# ESP32C3 register map
File version: 1.0
CPU: RISC-V RV32IMC single-core 1, little endian, no MPU, FPU, 3 interrupt priority bits
Registers are 32-bit, read-write, reset 0x0 unless marked. A register's access mark holds for its fields unless they carry their own. Offsets are from the block's base; [hi:lo] are bit positions; {n}, {i} and the like mark numbered series.

## RTCCNTL
Base 0x60008000
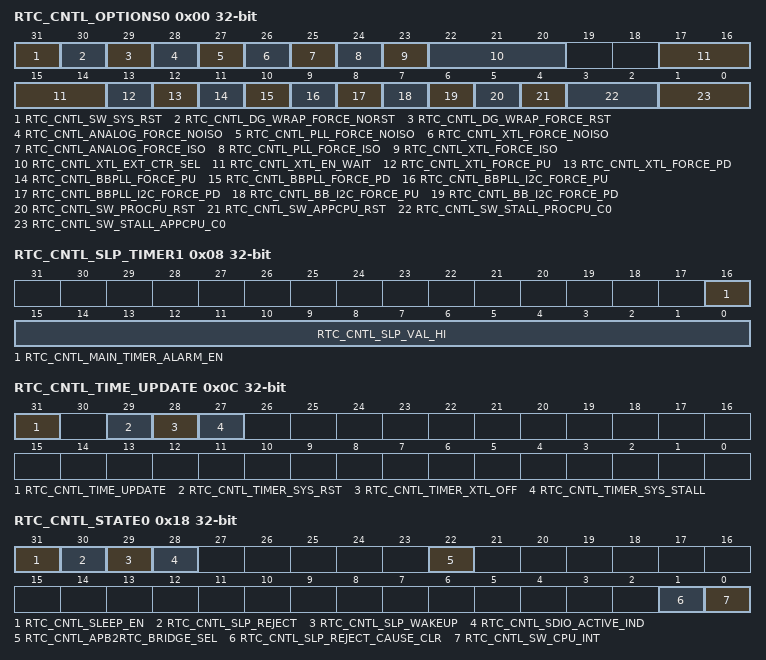
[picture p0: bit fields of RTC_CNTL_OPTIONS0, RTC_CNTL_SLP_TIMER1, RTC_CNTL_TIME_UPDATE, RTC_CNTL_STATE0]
0x00 RTC_CNTL_OPTIONS0 access per field
  [31] RTC_CNTL_SW_SYS_RST wo, [30] RTC_CNTL_DG_WRAP_FORCE_NORST rw, [29] RTC_CNTL_DG_WRAP_FORCE_RST rw, [28] RTC_CNTL_ANALOG_FORCE_NOISO rw, [27] RTC_CNTL_PLL_FORCE_NOISO rw, [26] RTC_CNTL_XTL_FORCE_NOISO rw, [25] RTC_CNTL_ANALOG_FORCE_ISO rw, [24] RTC_CNTL_PLL_FORCE_ISO rw, [23] RTC_CNTL_XTL_FORCE_ISO rw, [22:20] RTC_CNTL_XTL_EXT_CTR_SEL rw, [17:14] RTC_CNTL_XTL_EN_WAIT rw, [13] RTC_CNTL_XTL_FORCE_PU rw, [12] RTC_CNTL_XTL_FORCE_PD rw, [11] RTC_CNTL_BBPLL_FORCE_PU rw, [10] RTC_CNTL_BBPLL_FORCE_PD rw, [9] RTC_CNTL_BBPLL_I2C_FORCE_PU rw, [8] RTC_CNTL_BBPLL_I2C_FORCE_PD rw, [7] RTC_CNTL_BB_I2C_FORCE_PU rw, [6] RTC_CNTL_BB_I2C_FORCE_PD rw, [5] RTC_CNTL_SW_PROCPU_RST wo, [4] RTC_CNTL_SW_APPCPU_RST wo, [3:2] RTC_CNTL_SW_STALL_PROCPU_C0 rw, [1:0] RTC_CNTL_SW_STALL_APPCPU_C0 rw
0x04 RTC_CNTL_SLP_TIMER0
  [31:0] RTC_CNTL_SLP_VAL_LO
0x08 RTC_CNTL_SLP_TIMER1 access per field
  [16] RTC_CNTL_MAIN_TIMER_ALARM_EN wo, [15:0] RTC_CNTL_SLP_VAL_HI rw
0x0C RTC_CNTL_TIME_UPDATE access per field
  [31] RTC_CNTL_TIME_UPDATE wo, [29] RTC_CNTL_TIMER_SYS_RST rw, [28] RTC_CNTL_TIMER_XTL_OFF rw, [27] RTC_CNTL_TIMER_SYS_STALL rw
0x10 RTC_CNTL_TIME_LOW0 ro
  [31:0] RTC_CNTL_TIMER_VALUE0_LOW
0x14 RTC_CNTL_TIME_HIGH0 ro
  [15:0] RTC_CNTL_TIMER_VALUE0_HIGH
0x18 RTC_CNTL_STATE0 access per field
  [31] RTC_CNTL_SLEEP_EN rw, [30] RTC_CNTL_SLP_REJECT rw, [29] RTC_CNTL_SLP_WAKEUP rw, [28] RTC_CNTL_SDIO_ACTIVE_IND ro, [22] RTC_CNTL_APB2RTC_BRIDGE_SEL rw, [1] RTC_CNTL_SLP_REJECT_CAUSE_CLR wo, [0] RTC_CNTL_SW_CPU_INT wo
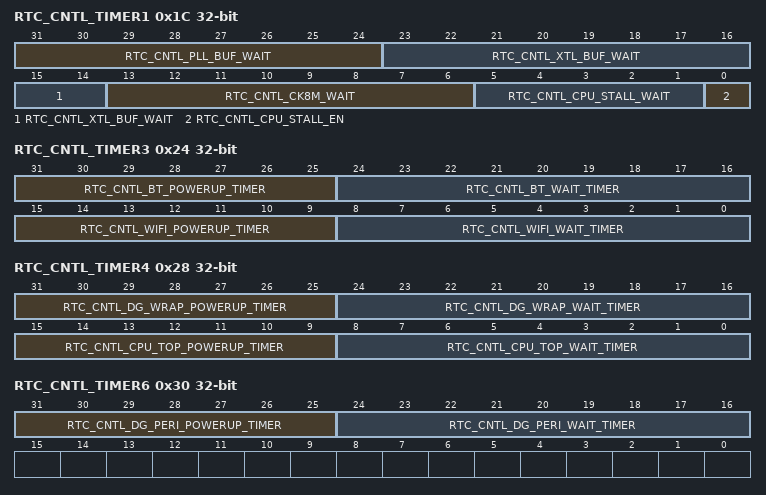
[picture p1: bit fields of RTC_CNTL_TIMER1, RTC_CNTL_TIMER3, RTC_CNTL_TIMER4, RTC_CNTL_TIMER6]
0x1C RTC_CNTL_TIMER1
  [31:24] RTC_CNTL_PLL_BUF_WAIT, [23:14] RTC_CNTL_XTL_BUF_WAIT, [13:6] RTC_CNTL_CK8M_WAIT, [5:1] RTC_CNTL_CPU_STALL_WAIT, [0] RTC_CNTL_CPU_STALL_EN
0x20 RTC_CNTL_TIMER2
  [31:24] RTC_CNTL_MIN_TIME_CK8M_OFF
0x24 RTC_CNTL_TIMER3
  [31:25] RTC_CNTL_BT_POWERUP_TIMER, [24:16] RTC_CNTL_BT_WAIT_TIMER, [15:9] RTC_CNTL_WIFI_POWERUP_TIMER, [8:0] RTC_CNTL_WIFI_WAIT_TIMER
0x28 RTC_CNTL_TIMER4
  [31:25] RTC_CNTL_DG_WRAP_POWERUP_TIMER, [24:16] RTC_CNTL_DG_WRAP_WAIT_TIMER, [15:9] RTC_CNTL_CPU_TOP_POWERUP_TIMER, [8:0] RTC_CNTL_CPU_TOP_WAIT_TIMER
0x2C RTC_CNTL_TIMER5
  [15:8] RTC_CNTL_MIN_SLP_VAL
0x30 RTC_CNTL_TIMER6
  [31:25] RTC_CNTL_DG_PERI_POWERUP_TIMER, [24:16] RTC_CNTL_DG_PERI_WAIT_TIMER
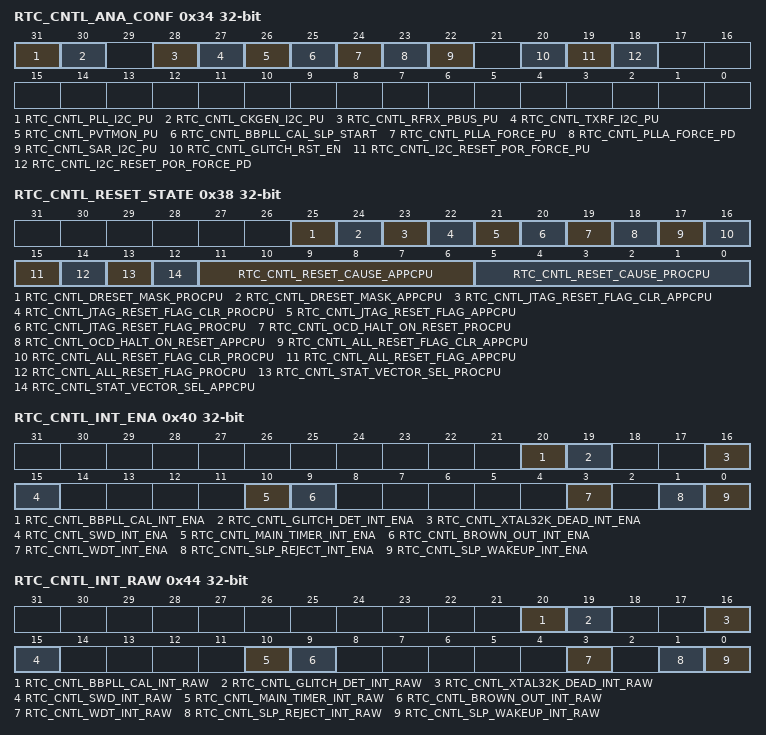
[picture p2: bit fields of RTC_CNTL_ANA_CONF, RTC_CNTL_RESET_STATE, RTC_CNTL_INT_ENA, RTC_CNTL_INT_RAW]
0x34 RTC_CNTL_ANA_CONF
  [31] RTC_CNTL_PLL_I2C_PU, [30] RTC_CNTL_CKGEN_I2C_PU, [28] RTC_CNTL_RFRX_PBUS_PU, [27] RTC_CNTL_TXRF_I2C_PU, [26] RTC_CNTL_PVTMON_PU, [25] RTC_CNTL_BBPLL_CAL_SLP_START, [24] RTC_CNTL_PLLA_FORCE_PU, [23] RTC_CNTL_PLLA_FORCE_PD, [22] RTC_CNTL_SAR_I2C_PU, [20] RTC_CNTL_GLITCH_RST_EN, [19] RTC_CNTL_I2C_RESET_POR_FORCE_PU, [18] RTC_CNTL_I2C_RESET_POR_FORCE_PD
0x38 RTC_CNTL_RESET_STATE access per field
  [25] RTC_CNTL_DRESET_MASK_PROCPU rw, [24] RTC_CNTL_DRESET_MASK_APPCPU rw, [23] RTC_CNTL_JTAG_RESET_FLAG_CLR_APPCPU wo, [22] RTC_CNTL_JTAG_RESET_FLAG_CLR_PROCPU wo, [21] RTC_CNTL_JTAG_RESET_FLAG_APPCPU ro, [20] RTC_CNTL_JTAG_RESET_FLAG_PROCPU ro, [19] RTC_CNTL_OCD_HALT_ON_RESET_PROCPU rw, [18] RTC_CNTL_OCD_HALT_ON_RESET_APPCPU rw, [17] RTC_CNTL_ALL_RESET_FLAG_CLR_APPCPU wo, [16] RTC_CNTL_ALL_RESET_FLAG_CLR_PROCPU wo, [15] RTC_CNTL_ALL_RESET_FLAG_APPCPU ro, [14] RTC_CNTL_ALL_RESET_FLAG_PROCPU ro, [13] RTC_CNTL_STAT_VECTOR_SEL_PROCPU rw, [12] RTC_CNTL_STAT_VECTOR_SEL_APPCPU rw, [11:6] RTC_CNTL_RESET_CAUSE_APPCPU ro, [5:0] RTC_CNTL_RESET_CAUSE_PROCPU ro
0x3C RTC_CNTL_WAKEUP_STATE
  [31:15] RTC_CNTL_WAKEUP_ENA
0x40 RTC_CNTL_INT_ENA
  [20] RTC_CNTL_BBPLL_CAL_INT_ENA, [19] RTC_CNTL_GLITCH_DET_INT_ENA, [16] RTC_CNTL_XTAL32K_DEAD_INT_ENA, [15] RTC_CNTL_SWD_INT_ENA, [10] RTC_CNTL_MAIN_TIMER_INT_ENA, [9] RTC_CNTL_BROWN_OUT_INT_ENA, [3] RTC_CNTL_WDT_INT_ENA, [1] RTC_CNTL_SLP_REJECT_INT_ENA, [0] RTC_CNTL_SLP_WAKEUP_INT_ENA
0x44 RTC_CNTL_INT_RAW ro
  [20] RTC_CNTL_BBPLL_CAL_INT_RAW, [19] RTC_CNTL_GLITCH_DET_INT_RAW, [16] RTC_CNTL_XTAL32K_DEAD_INT_RAW, [15] RTC_CNTL_SWD_INT_RAW, [10] RTC_CNTL_MAIN_TIMER_INT_RAW, [9] RTC_CNTL_BROWN_OUT_INT_RAW, [3] RTC_CNTL_WDT_INT_RAW, [1] RTC_CNTL_SLP_REJECT_INT_RAW, [0] RTC_CNTL_SLP_WAKEUP_INT_RAW
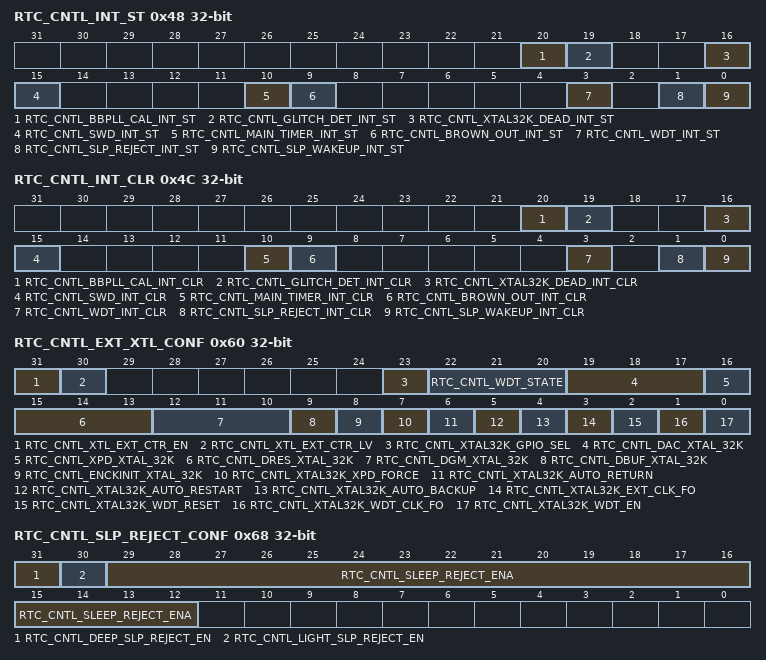
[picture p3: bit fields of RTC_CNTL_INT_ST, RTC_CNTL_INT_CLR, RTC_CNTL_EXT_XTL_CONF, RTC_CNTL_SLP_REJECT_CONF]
0x48 RTC_CNTL_INT_ST ro
  [20] RTC_CNTL_BBPLL_CAL_INT_ST, [19] RTC_CNTL_GLITCH_DET_INT_ST, [16] RTC_CNTL_XTAL32K_DEAD_INT_ST, [15] RTC_CNTL_SWD_INT_ST, [10] RTC_CNTL_MAIN_TIMER_INT_ST, [9] RTC_CNTL_BROWN_OUT_INT_ST, [3] RTC_CNTL_WDT_INT_ST, [1] RTC_CNTL_SLP_REJECT_INT_ST, [0] RTC_CNTL_SLP_WAKEUP_INT_ST
0x4C RTC_CNTL_INT_CLR wo
  [20] RTC_CNTL_BBPLL_CAL_INT_CLR, [19] RTC_CNTL_GLITCH_DET_INT_CLR, [16] RTC_CNTL_XTAL32K_DEAD_INT_CLR, [15] RTC_CNTL_SWD_INT_CLR, [10] RTC_CNTL_MAIN_TIMER_INT_CLR, [9] RTC_CNTL_BROWN_OUT_INT_CLR, [3] RTC_CNTL_WDT_INT_CLR, [1] RTC_CNTL_SLP_REJECT_INT_CLR, [0] RTC_CNTL_SLP_WAKEUP_INT_CLR
{0x50+4i} RTC_CNTL_STORE{i} (i=0..3)
  [31:0] RTC_CNTL_SCRATCH{i}
0x60 RTC_CNTL_EXT_XTL_CONF access per field
  [31] RTC_CNTL_XTL_EXT_CTR_EN rw, [30] RTC_CNTL_XTL_EXT_CTR_LV rw, [23] RTC_CNTL_XTAL32K_GPIO_SEL rw, [22:20] RTC_CNTL_WDT_STATE ro, [19:17] RTC_CNTL_DAC_XTAL_32K rw, [16] RTC_CNTL_XPD_XTAL_32K rw, [15:13] RTC_CNTL_DRES_XTAL_32K rw, [12:10] RTC_CNTL_DGM_XTAL_32K rw, [9] RTC_CNTL_DBUF_XTAL_32K rw, [8] RTC_CNTL_ENCKINIT_XTAL_32K rw, [7] RTC_CNTL_XTAL32K_XPD_FORCE rw, [6] RTC_CNTL_XTAL32K_AUTO_RETURN rw, [5] RTC_CNTL_XTAL32K_AUTO_RESTART rw, [4] RTC_CNTL_XTAL32K_AUTO_BACKUP rw, [3] RTC_CNTL_XTAL32K_EXT_CLK_FO rw, [2] RTC_CNTL_XTAL32K_WDT_RESET rw, [1] RTC_CNTL_XTAL32K_WDT_CLK_FO rw, [0] RTC_CNTL_XTAL32K_WDT_EN rw
0x64 RTC_CNTL_EXT_WAKEUP_CONF
  [31] RTC_CNTL_GPIO_WAKEUP_FILTER
0x68 RTC_CNTL_SLP_REJECT_CONF
  [31] RTC_CNTL_DEEP_SLP_REJECT_EN, [30] RTC_CNTL_LIGHT_SLP_REJECT_EN, [29:12] RTC_CNTL_SLEEP_REJECT_ENA
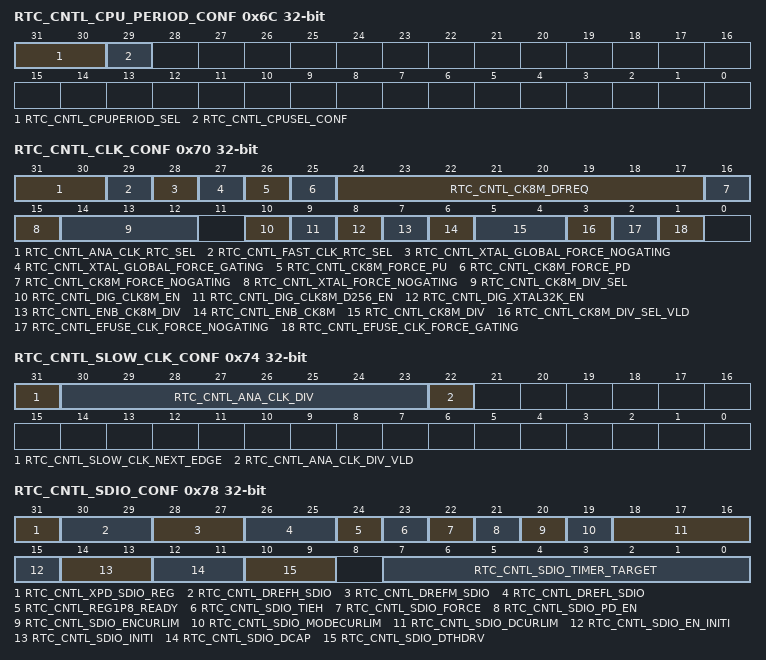
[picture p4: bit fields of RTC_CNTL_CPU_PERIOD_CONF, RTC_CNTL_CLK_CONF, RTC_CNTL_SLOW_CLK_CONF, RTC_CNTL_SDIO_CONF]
0x6C RTC_CNTL_CPU_PERIOD_CONF
  [31:30] RTC_CNTL_CPUPERIOD_SEL, [29] RTC_CNTL_CPUSEL_CONF
0x70 RTC_CNTL_CLK_CONF
  [31:30] RTC_CNTL_ANA_CLK_RTC_SEL, [29] RTC_CNTL_FAST_CLK_RTC_SEL, [28] RTC_CNTL_XTAL_GLOBAL_FORCE_NOGATING, [27] RTC_CNTL_XTAL_GLOBAL_FORCE_GATING, [26] RTC_CNTL_CK8M_FORCE_PU, [25] RTC_CNTL_CK8M_FORCE_PD, [24:17] RTC_CNTL_CK8M_DFREQ, [16] RTC_CNTL_CK8M_FORCE_NOGATING, [15] RTC_CNTL_XTAL_FORCE_NOGATING, [14:12] RTC_CNTL_CK8M_DIV_SEL, [10] RTC_CNTL_DIG_CLK8M_EN, [9] RTC_CNTL_DIG_CLK8M_D256_EN, [8] RTC_CNTL_DIG_XTAL32K_EN, [7] RTC_CNTL_ENB_CK8M_DIV, [6] RTC_CNTL_ENB_CK8M, [5:4] RTC_CNTL_CK8M_DIV, [3] RTC_CNTL_CK8M_DIV_SEL_VLD, [2] RTC_CNTL_EFUSE_CLK_FORCE_NOGATING, [1] RTC_CNTL_EFUSE_CLK_FORCE_GATING
0x74 RTC_CNTL_SLOW_CLK_CONF
  [31] RTC_CNTL_SLOW_CLK_NEXT_EDGE, [30:23] RTC_CNTL_ANA_CLK_DIV, [22] RTC_CNTL_ANA_CLK_DIV_VLD
0x78 RTC_CNTL_SDIO_CONF access per field
  [31] RTC_CNTL_XPD_SDIO_REG rw, [30:29] RTC_CNTL_DREFH_SDIO rw, [28:27] RTC_CNTL_DREFM_SDIO rw, [26:25] RTC_CNTL_DREFL_SDIO rw, [24] RTC_CNTL_REG1P8_READY ro, [23] RTC_CNTL_SDIO_TIEH rw, [22] RTC_CNTL_SDIO_FORCE rw, [21] RTC_CNTL_SDIO_PD_EN rw, [20] RTC_CNTL_SDIO_ENCURLIM rw, [19] RTC_CNTL_SDIO_MODECURLIM rw, [18:16] RTC_CNTL_SDIO_DCURLIM rw, [15] RTC_CNTL_SDIO_EN_INITI rw, [14:13] RTC_CNTL_SDIO_INITI rw, [12:11] RTC_CNTL_SDIO_DCAP rw, [10:9] RTC_CNTL_SDIO_DTHDRV rw, [7:0] RTC_CNTL_SDIO_TIMER_TARGET rw
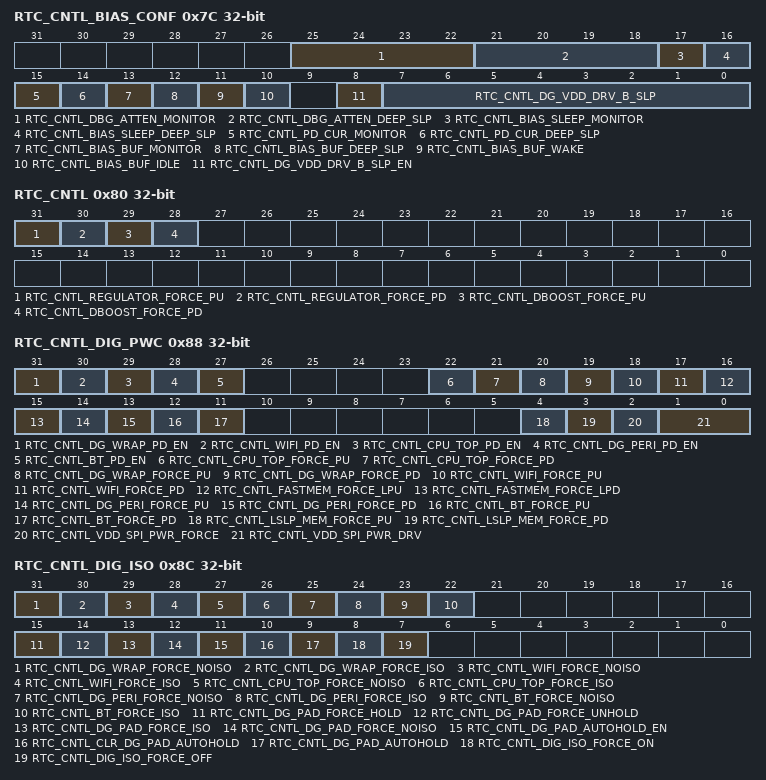
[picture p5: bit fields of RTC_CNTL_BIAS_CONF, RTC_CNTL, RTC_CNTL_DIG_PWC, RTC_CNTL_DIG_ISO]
0x7C RTC_CNTL_BIAS_CONF
  [25:22] RTC_CNTL_DBG_ATTEN_MONITOR, [21:18] RTC_CNTL_DBG_ATTEN_DEEP_SLP, [17] RTC_CNTL_BIAS_SLEEP_MONITOR, [16] RTC_CNTL_BIAS_SLEEP_DEEP_SLP, [15] RTC_CNTL_PD_CUR_MONITOR, [14] RTC_CNTL_PD_CUR_DEEP_SLP, [13] RTC_CNTL_BIAS_BUF_MONITOR, [12] RTC_CNTL_BIAS_BUF_DEEP_SLP, [11] RTC_CNTL_BIAS_BUF_WAKE, [10] RTC_CNTL_BIAS_BUF_IDLE, [8] RTC_CNTL_DG_VDD_DRV_B_SLP_EN, [7:0] RTC_CNTL_DG_VDD_DRV_B_SLP
0x80 RTC_CNTL
  [31] RTC_CNTL_REGULATOR_FORCE_PU, [30] RTC_CNTL_REGULATOR_FORCE_PD, [29] RTC_CNTL_DBOOST_FORCE_PU, [28] RTC_CNTL_DBOOST_FORCE_PD
0x84 RTC_CNTL_PWC
  [21] RTC_CNTL_PAD_FORCE_HOLD
0x88 RTC_CNTL_DIG_PWC
  [31] RTC_CNTL_DG_WRAP_PD_EN, [30] RTC_CNTL_WIFI_PD_EN, [29] RTC_CNTL_CPU_TOP_PD_EN, [28] RTC_CNTL_DG_PERI_PD_EN, [27] RTC_CNTL_BT_PD_EN, [22] RTC_CNTL_CPU_TOP_FORCE_PU, [21] RTC_CNTL_CPU_TOP_FORCE_PD, [20] RTC_CNTL_DG_WRAP_FORCE_PU, [19] RTC_CNTL_DG_WRAP_FORCE_PD, [18] RTC_CNTL_WIFI_FORCE_PU, [17] RTC_CNTL_WIFI_FORCE_PD, [16] RTC_CNTL_FASTMEM_FORCE_LPU, [15] RTC_CNTL_FASTMEM_FORCE_LPD, [14] RTC_CNTL_DG_PERI_FORCE_PU, [13] RTC_CNTL_DG_PERI_FORCE_PD, [12] RTC_CNTL_BT_FORCE_PU, [11] RTC_CNTL_BT_FORCE_PD, [4] RTC_CNTL_LSLP_MEM_FORCE_PU, [3] RTC_CNTL_LSLP_MEM_FORCE_PD, [2] RTC_CNTL_VDD_SPI_PWR_FORCE, [1:0] RTC_CNTL_VDD_SPI_PWR_DRV
0x8C RTC_CNTL_DIG_ISO access per field
  [31] RTC_CNTL_DG_WRAP_FORCE_NOISO rw, [30] RTC_CNTL_DG_WRAP_FORCE_ISO rw, [29] RTC_CNTL_WIFI_FORCE_NOISO rw, [28] RTC_CNTL_WIFI_FORCE_ISO rw, [27] RTC_CNTL_CPU_TOP_FORCE_NOISO rw, [26] RTC_CNTL_CPU_TOP_FORCE_ISO rw, [25] RTC_CNTL_DG_PERI_FORCE_NOISO rw, [24] RTC_CNTL_DG_PERI_FORCE_ISO rw, [23] RTC_CNTL_BT_FORCE_NOISO rw, [22] RTC_CNTL_BT_FORCE_ISO rw, [15] RTC_CNTL_DG_PAD_FORCE_HOLD rw, [14] RTC_CNTL_DG_PAD_FORCE_UNHOLD rw, [13] RTC_CNTL_DG_PAD_FORCE_ISO rw, [12] RTC_CNTL_DG_PAD_FORCE_NOISO rw, [11] RTC_CNTL_DG_PAD_AUTOHOLD_EN rw, [10] RTC_CNTL_CLR_DG_PAD_AUTOHOLD wo, [9] RTC_CNTL_DG_PAD_AUTOHOLD ro, [8] RTC_CNTL_DIG_ISO_FORCE_ON rw, [7] RTC_CNTL_DIG_ISO_FORCE_OFF rw
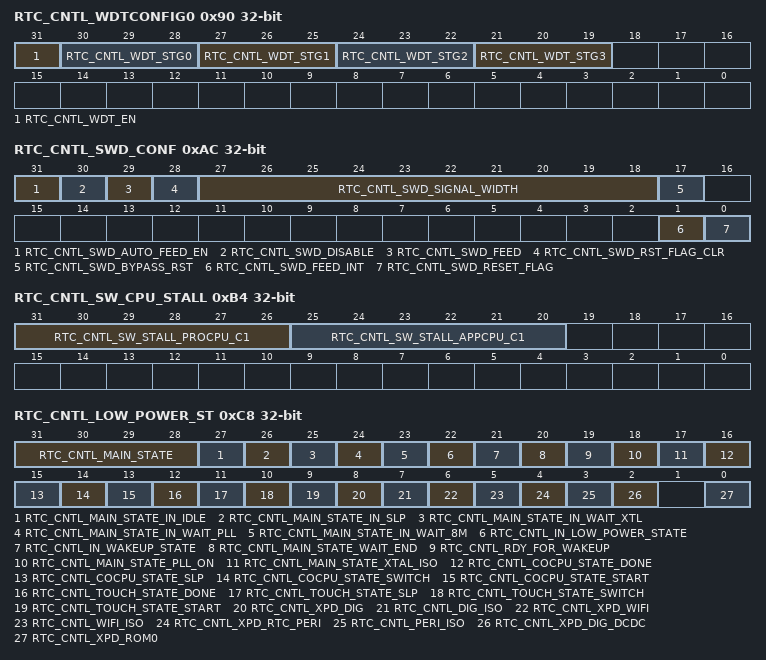
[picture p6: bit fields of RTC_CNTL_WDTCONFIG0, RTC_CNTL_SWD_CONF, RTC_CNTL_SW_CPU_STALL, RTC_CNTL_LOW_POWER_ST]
0x90 RTC_CNTL_WDTCONFIG0
  [31] RTC_CNTL_WDT_EN, [30-3n:28-3n] RTC_CNTL_WDT_STG{n} (n=0..3)
{0x90+4i} RTC_CNTL_WDTCONFIG{i} (i=1..4)
  [31:0] RTC_CNTL_WDT_STG{i-1}_HOLD
0xA4 RTC_CNTL_WDTFEED wo
  [31] RTC_CNTL_WDT_FEED
0xA8 RTC_CNTL_WDTWPROTECT
  [31:0] RTC_CNTL_WDT_WKEY
0xAC RTC_CNTL_SWD_CONF access per field
  [31] RTC_CNTL_SWD_AUTO_FEED_EN rw, [30] RTC_CNTL_SWD_DISABLE rw, [29] RTC_CNTL_SWD_FEED wo, [28] RTC_CNTL_SWD_RST_FLAG_CLR wo, [27:18] RTC_CNTL_SWD_SIGNAL_WIDTH rw, [17] RTC_CNTL_SWD_BYPASS_RST rw, [1] RTC_CNTL_SWD_FEED_INT ro, [0] RTC_CNTL_SWD_RESET_FLAG ro
0xB0 RTC_CNTL_SWD_WPROTECT
  [31:0] RTC_CNTL_SWD_WKEY
0xB4 RTC_CNTL_SW_CPU_STALL
  [31:26] RTC_CNTL_SW_STALL_PROCPU_C1, [25:20] RTC_CNTL_SW_STALL_APPCPU_C1
{0xA8+4i} RTC_CNTL_STORE{i} (i=4..7)
  [31:0] RTC_CNTL_SCRATCH{i}
0xC8 RTC_CNTL_LOW_POWER_ST ro
  [31:28] RTC_CNTL_MAIN_STATE, [27] RTC_CNTL_MAIN_STATE_IN_IDLE, [26] RTC_CNTL_MAIN_STATE_IN_SLP, [25] RTC_CNTL_MAIN_STATE_IN_WAIT_XTL, [24] RTC_CNTL_MAIN_STATE_IN_WAIT_PLL, [23] RTC_CNTL_MAIN_STATE_IN_WAIT_8M, [22] RTC_CNTL_IN_LOW_POWER_STATE, [21] RTC_CNTL_IN_WAKEUP_STATE, [20] RTC_CNTL_MAIN_STATE_WAIT_END, [19] RTC_CNTL_RDY_FOR_WAKEUP, [18] RTC_CNTL_MAIN_STATE_PLL_ON, [17] RTC_CNTL_MAIN_STATE_XTAL_ISO, [16] RTC_CNTL_COCPU_STATE_DONE, [15] RTC_CNTL_COCPU_STATE_SLP, [14] RTC_CNTL_COCPU_STATE_SWITCH, [13] RTC_CNTL_COCPU_STATE_START, [12] RTC_CNTL_TOUCH_STATE_DONE, [11] RTC_CNTL_TOUCH_STATE_SLP, [10] RTC_CNTL_TOUCH_STATE_SWITCH, [9] RTC_CNTL_TOUCH_STATE_START, [8] RTC_CNTL_XPD_DIG, [7] RTC_CNTL_DIG_ISO, [6] RTC_CNTL_XPD_WIFI, [5] RTC_CNTL_WIFI_ISO, [4] RTC_CNTL_XPD_RTC_PERI, [3] RTC_CNTL_PERI_ISO, [2] RTC_CNTL_XPD_DIG_DCDC, [0] RTC_CNTL_XPD_ROM0
0xCC RTC_CNTL_DIAG0 ro
  [31:0] RTC_CNTL_LOW_POWER_DIAG1
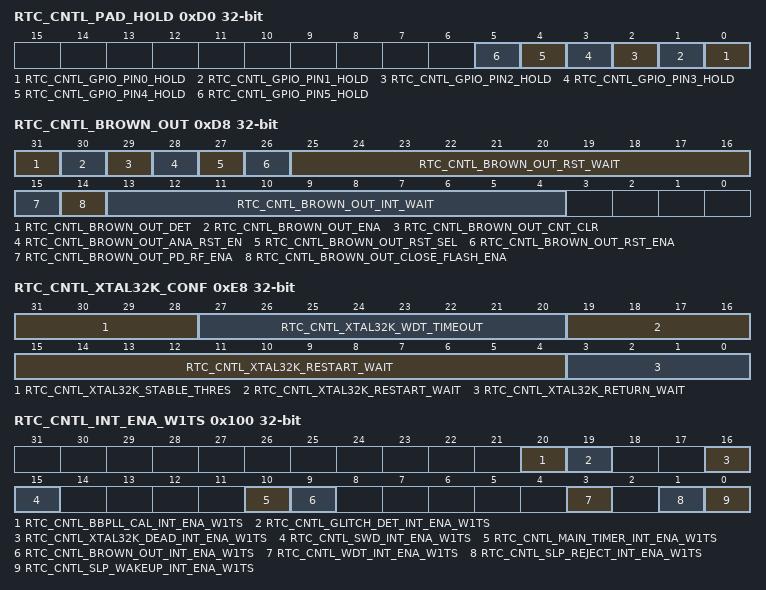
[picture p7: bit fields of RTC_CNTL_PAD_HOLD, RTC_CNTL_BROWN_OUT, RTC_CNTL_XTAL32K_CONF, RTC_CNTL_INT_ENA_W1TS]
0xD0 RTC_CNTL_PAD_HOLD
  [n] RTC_CNTL_GPIO_PIN{n}_HOLD (n=0..5)
0xD4 RTC_CNTL_DIG_PAD_HOLD
0xD8 RTC_CNTL_BROWN_OUT access per field
  [31] RTC_CNTL_BROWN_OUT_DET ro, [30] RTC_CNTL_BROWN_OUT_ENA rw, [29] RTC_CNTL_BROWN_OUT_CNT_CLR wo, [28] RTC_CNTL_BROWN_OUT_ANA_RST_EN rw, [27] RTC_CNTL_BROWN_OUT_RST_SEL rw, [26] RTC_CNTL_BROWN_OUT_RST_ENA rw, [25:16] RTC_CNTL_BROWN_OUT_RST_WAIT rw, [15] RTC_CNTL_BROWN_OUT_PD_RF_ENA rw, [14] RTC_CNTL_BROWN_OUT_CLOSE_FLASH_ENA rw, [13:4] RTC_CNTL_BROWN_OUT_INT_WAIT rw
0xDC RTC_CNTL_TIME_LOW1 ro
  [31:0] RTC_CNTL_TIMER_VALUE1_LOW
0xE0 RTC_CNTL_TIME_HIGH1 ro
  [15:0] RTC_CNTL_TIMER_VALUE1_HIGH
0xE4 RTC_CNTL_XTAL32K_CLK_FACTOR
0xE8 RTC_CNTL_XTAL32K_CONF
  [31:28] RTC_CNTL_XTAL32K_STABLE_THRES, [27:20] RTC_CNTL_XTAL32K_WDT_TIMEOUT, [19:4] RTC_CNTL_XTAL32K_RESTART_WAIT, [3:0] RTC_CNTL_XTAL32K_RETURN_WAIT
0xEC RTC_CNTL_USB_CONF
  [18] RTC_CNTL_IO_MUX_RESET_DISABLE
0xF0 RTC_CNTL_SLP_REJECT_CAUSE ro
  [17:0] RTC_CNTL_REJECT_CAUSE
0xF4 RTC_CNTL_OPTION1
  [0] RTC_CNTL_FORCE_DOWNLOAD_BOOT
0xF8 RTC_CNTL_SLP_WAKEUP_CAUSE ro
  [16:0] RTC_CNTL_WAKEUP_CAUSE
0xFC RTC_CNTL_ULP_CP_TIMER_1
  [31:8] RTC_CNTL_ULP_CP_TIMER_SLP_CYCLE
0x100 RTC_CNTL_INT_ENA_W1TS wo
  [20] RTC_CNTL_BBPLL_CAL_INT_ENA_W1TS, [19] RTC_CNTL_GLITCH_DET_INT_ENA_W1TS, [16] RTC_CNTL_XTAL32K_DEAD_INT_ENA_W1TS, [15] RTC_CNTL_SWD_INT_ENA_W1TS, [10] RTC_CNTL_MAIN_TIMER_INT_ENA_W1TS, [9] RTC_CNTL_BROWN_OUT_INT_ENA_W1TS, [3] RTC_CNTL_WDT_INT_ENA_W1TS, [1] RTC_CNTL_SLP_REJECT_INT_ENA_W1TS, [0] RTC_CNTL_SLP_WAKEUP_INT_ENA_W1TS
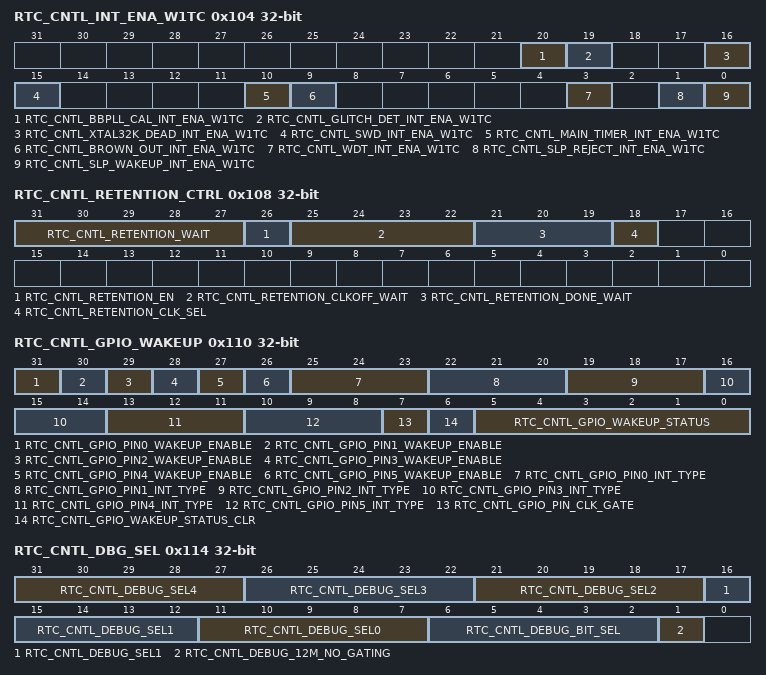
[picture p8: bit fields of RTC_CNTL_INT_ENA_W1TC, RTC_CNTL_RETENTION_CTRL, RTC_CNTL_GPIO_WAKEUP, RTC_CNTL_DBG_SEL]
0x104 RTC_CNTL_INT_ENA_W1TC wo
  [20] RTC_CNTL_BBPLL_CAL_INT_ENA_W1TC, [19] RTC_CNTL_GLITCH_DET_INT_ENA_W1TC, [16] RTC_CNTL_XTAL32K_DEAD_INT_ENA_W1TC, [15] RTC_CNTL_SWD_INT_ENA_W1TC, [10] RTC_CNTL_MAIN_TIMER_INT_ENA_W1TC, [9] RTC_CNTL_BROWN_OUT_INT_ENA_W1TC, [3] RTC_CNTL_WDT_INT_ENA_W1TC, [1] RTC_CNTL_SLP_REJECT_INT_ENA_W1TC, [0] RTC_CNTL_SLP_WAKEUP_INT_ENA_W1TC
0x108 RTC_CNTL_RETENTION_CTRL
  [31:27] RTC_CNTL_RETENTION_WAIT, [26] RTC_CNTL_RETENTION_EN, [25:22] RTC_CNTL_RETENTION_CLKOFF_WAIT, [21:19] RTC_CNTL_RETENTION_DONE_WAIT, [18] RTC_CNTL_RETENTION_CLK_SEL
0x10C RTC_CNTL_FIB_SEL
  [2:0] RTC_CNTL_FIB_SEL
0x110 RTC_CNTL_GPIO_WAKEUP access per field
  [31-n] RTC_CNTL_GPIO_PIN{n}_WAKEUP_ENABLE rw (n=0..5), [25-3n:23-3n] RTC_CNTL_GPIO_PIN{n}_INT_TYPE rw (n=0..5), [7] RTC_CNTL_GPIO_PIN_CLK_GATE rw, [6] RTC_CNTL_GPIO_WAKEUP_STATUS_CLR rw, [5:0] RTC_CNTL_GPIO_WAKEUP_STATUS ro
0x114 RTC_CNTL_DBG_SEL
  [5n+11:5n+7] RTC_CNTL_DEBUG_SEL{n} (n=0..4), [6:2] RTC_CNTL_DEBUG_BIT_SEL, [1] RTC_CNTL_DEBUG_12M_NO_GATING
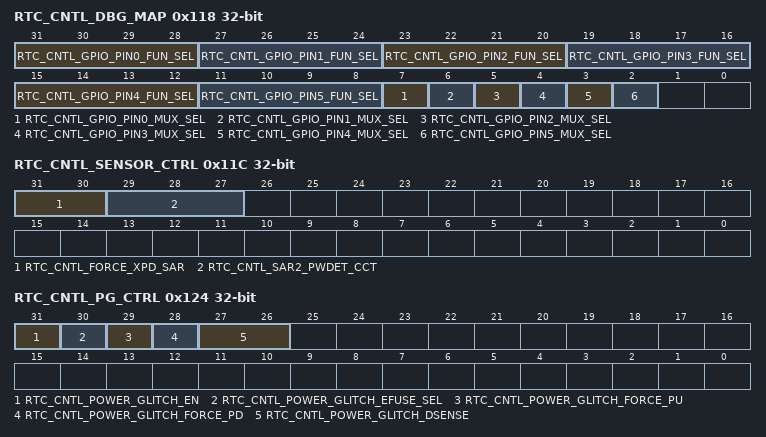
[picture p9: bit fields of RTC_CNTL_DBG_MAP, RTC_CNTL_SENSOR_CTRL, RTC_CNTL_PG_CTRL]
0x118 RTC_CNTL_DBG_MAP
  [31-4n:28-4n] RTC_CNTL_GPIO_PIN{n}_FUN_SEL (n=0..5), [7-n] RTC_CNTL_GPIO_PIN{n}_MUX_SEL (n=0..5)
0x11C RTC_CNTL_SENSOR_CTRL
  [31:30] RTC_CNTL_FORCE_XPD_SAR, [29:27] RTC_CNTL_SAR2_PWDET_CCT
0x120 RTC_CNTL_DBG_SAR_SEL
  [31:27] RTC_CNTL_SAR_DEBUG_SEL
0x124 RTC_CNTL_PG_CTRL
  [31] RTC_CNTL_POWER_GLITCH_EN, [30] RTC_CNTL_POWER_GLITCH_EFUSE_SEL, [29] RTC_CNTL_POWER_GLITCH_FORCE_PU, [28] RTC_CNTL_POWER_GLITCH_FORCE_PD, [27:26] RTC_CNTL_POWER_GLITCH_DSENSE
0x1FC RTC_CNTL_DATE
  [27:0] RTC_CNTL_CNTL_DATE
